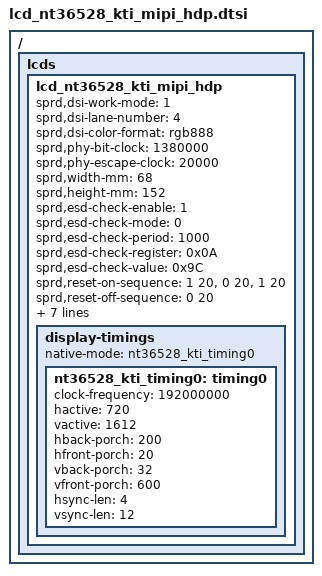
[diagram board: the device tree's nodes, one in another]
// SPDX-License-Identifier: GPL-2.0-only
/*
 * G3655 VISIONOX AMOLED config dtsi file for spreadtrum
 *
 * Copyright (C) 2021, Spreadtrum Communications Inc.
 */
/ {
	fragment {
		target-path = "/";
		__overlay__ {
			lcds {
				lcd_nt36528_kti_mipi_hdp: lcd_nt36528_kti_mipi_hdp {

					sprd,dsi-work-mode = <1>; /* video burst mode*/
					sprd,dsi-lane-number = <4>;
					sprd,dsi-color-format = "rgb888";

					sprd,phy-bit-clock = <1380000>;  /* kbps */
					sprd,phy-escape-clock = <20000>;/* kHz */

					sprd,width-mm = <68>;
					sprd,height-mm = <152>;

					sprd,esd-check-enable = <1>;
					sprd,esd-check-mode = <0>;  // 0:Reg mode 1:TE mode
					sprd,esd-check-period = <1000>;
					sprd,esd-check-register = <0x0A>;
					sprd,esd-check-value = <0x9C>;

					sprd,reset-on-sequence = <1 20>, <0 20>, <1 20>;
					sprd,reset-off-sequence = <0 20>;

					sprd,use-gen-write;

					sprd,initial-command = [
						15 05 00 02 FF 20
						15 00 00 02 FB 01
						15 00 00 02 05 AB
						15 00 00 02 08 64
						15 00 00 02 0D 80
						15 00 00 02 80 64
						15 00 00 02 94 C0
						15 00 00 02 95 09
						15 00 00 02 96 09

						15 05 00 02 FF 24

						15 00 00 02 FB 01
						15 00 00 02 00 26
						15 00 00 02 01 26
						15 00 00 02 02 08
						15 00 00 02 03 21
						15 00 00 02 04 04
						15 00 00 02 05 05
						15 00 00 02 06 06
						15 00 00 02 07 27
						15 00 00 02 08 0C
						15 00 00 02 09 0C
						15 00 00 02 0A 0D
						15 00 00 02 0B 0D
						15 00 00 02 0C 0E
						15 00 00 02 0D 0E
						15 00 00 02 0E 0F
						15 00 00 02 0F 0F
						15 00 00 02 10 10
						15 00 00 02 11 10
						15 00 00 02 12 11
						15 00 00 02 13 11
						15 00 00 02 14 26
						15 00 00 02 15 03
						15 00 00 02 16 26
						15 00 00 02 17 26
						15 00 00 02 18 08
						15 00 00 02 19 21
						15 00 00 02 1A 04
						15 00 00 02 1B 05
						15 00 00 02 1C 06
						15 00 00 02 1D 27
						15 00 00 02 1E 0C
						15 00 00 02 1F 0C
						15 00 00 02 20 0D
						15 00 00 02 21 0D
						15 00 00 02 22 0E
						15 00 00 02 23 0E
						15 00 00 02 24 0F
						15 00 00 02 25 0F
						15 00 00 02 26 10
						15 00 00 02 27 10
						15 00 00 02 28 11
						15 00 00 02 29 11
						15 00 00 02 2A 26
						15 00 00 02 2B 03
						15 00 00 02 2F 0E
						15 00 00 02 30 0C
						15 00 00 02 31 0A
						15 00 00 02 37 77
						15 00 00 02 38 74
						15 00 00 02 3A 46
						15 00 00 02 3B 4D
						15 00 00 02 3F 45
						15 00 00 02 47 64
						15 00 00 02 4A 05
						15 00 00 02 4B 4E
						15 00 00 02 4C 91
						39 00 00 03 55 8C 03
						15 00 00 02 5C 88
						15 00 00 02 5D 0A
						15 00 00 03 5E 00 06
						15 00 00 02 96 02
						15 00 00 02 B0 0B
						15 00 00 02 B1 11
						15 00 00 02 B2 0C
						15 00 00 02 59 70
						15 00 00 02 5A 4C
						15 00 00 02 5B 40
						15 00 00 02 61 4C
						15 00 00 02 92 5C
						39 00 00 03 93 58 01
						15 00 00 02 94 15
						15 00 00 02 DC 57
						15 00 00 02 E0 57
						15 00 00 02 E2 57
						15 00 00 02 E4 57
						15 00 00 02 E6 B9
						15 00 00 02 EA 09
						15 00 00 02 EE B9
						15 00 00 02 F0 57

						15 05 00 02 FF 25

						15 00 00 02 FB 01
						39 00 00 05 02 00 00 00 40
						15 00 00 02 13 01
						15 00 00 02 14 21
						15 00 00 02 15 01
						15 00 00 02 16 21
						15 00 00 02 1F 4C
						15 00 00 02 20 40
						15 00 00 02 26 4C
						15 00 00 02 27 40
						15 00 00 02 40 00
						15 00 00 02 48 4C
						15 00 00 02 49 40
						15 00 00 02 50 4C
						15 00 00 02 51 40
						15 00 00 02 61 4C
						15 00 00 02 62 40
						15 00 00 02 68 06
						15 00 00 02 BD 8F

						15 05 00 02 FF 26

						15 00 00 02 FB 01
						15 00 00 02 02 0D
						15 00 00 02 04 35
						15 00 00 02 0A 05
						15 00 00 02 0C 31
						15 00 00 02 0F 00
						15 00 00 02 13 20
						15 00 00 02 14 00
						15 00 00 02 16 00
						15 00 00 02 1A AB
						15 00 00 02 1B 12
						15 00 00 02 1C 20
						15 00 00 02 1E 5C
						15 00 00 02 1F 5C
						15 00 00 02 24 00
						15 00 00 02 25 5C
						15 00 00 02 2A 12
						15 00 00 02 2B AB
						15 00 00 02 2F 00
						15 00 00 02 30 5C
						15 00 00 02 32 5C
						15 00 00 02 34 81
						15 00 00 02 35 67
						15 00 00 02 36 11
						15 00 00 02 37 11
						15 00 00 02 38 01
						15 00 00 02 39 0D
						15 00 00 02 3A 5C
						15 00 00 04 A9 00 21 22
						15 00 00 02 C3 B0
						15 00 00 02 C8 01
						15 00 00 02 C9 03
						15 00 00 02 CB 03

						15 05 00 02 FF 27

						15 00 00 02 FB 01
						15 00 00 02 E5 AF
						15 00 00 02 58 A8
						39 00 00 03 59 00 0B
						39 00 00 03 5A 00 01
						39 00 00 03 5D 00 0D
						39 00 00 03 5E 01 7C
						15 00 00 02 5F 01
						39 00 00 03 60 07 AE
						15 00 00 02 F0 77
						15 00 00 02 F4 00

						15 05 00 02 FF 2A

						15 00 00 02 FB 01
						15 00 00 02 6A 01
						15 00 00 02 A2 3F
						15 00 00 02 A3 0C
						15 00 00 02 A4 0F
						15 00 00 02 04 57
						15 00 00 02 06 57
						15 00 00 02 09 57
						15 00 00 02 0B 57
						15 00 00 02 0D 57
						15 00 00 02 14 57
						15 00 00 02 15 57
						15 00 00 02 16 57
						15 00 00 02 23 08
						15 00 00 02 2B 01
						15 00 00 02 2D 58
						15 00 00 02 33 0A
						15 00 00 02 35 0A
						15 00 00 02 37 0A
						15 00 00 02 99 95
						15 00 00 02 9A 0B
						15 00 00 02 AC 00
						15 00 00 02 AD 3C
						15 00 00 02 AE 80
						15 00 00 02 AF 43
						15 00 00 02 B0 18
						15 00 00 02 B1 90
						15 00 00 02 B3 66

						15 05 00 02 FF 23

						15 00 00 02 FB 01
						15 00 00 02 11 00
						15 00 00 02 12 B5
						15 00 00 02 15 E7
						15 00 00 02 16 14

						15 00 00 02 FF 10
						15 00 00 02 FB 01
						15 00 00 02 35 00

						05 C8 00 01 11
						05 32 00 01 29
						];

					sprd,sleep-in-command = [
						13 0A 00 01 28
						13 78 00 01 10
						23 0a 00 02 4f 01
						];
					sprd,sleep-out-command = [
						13 78 00 01 11
						13 32 00 01 29
						];

					display-timings {
						native-mode = <&nt36528_kti_timing0>;

						nt36528_kti_timing0: timing0 {
							clock-frequency = <192000000>;
							hactive = <720>;
							vactive = <1612>;
							hback-porch = <200>;
							hfront-porch = <20>;
							vback-porch = <32>;
							vfront-porch = <600>;
							hsync-len = <4>;
							vsync-len = <12>;
						};

					};
				};
			};
		};
	};
};
